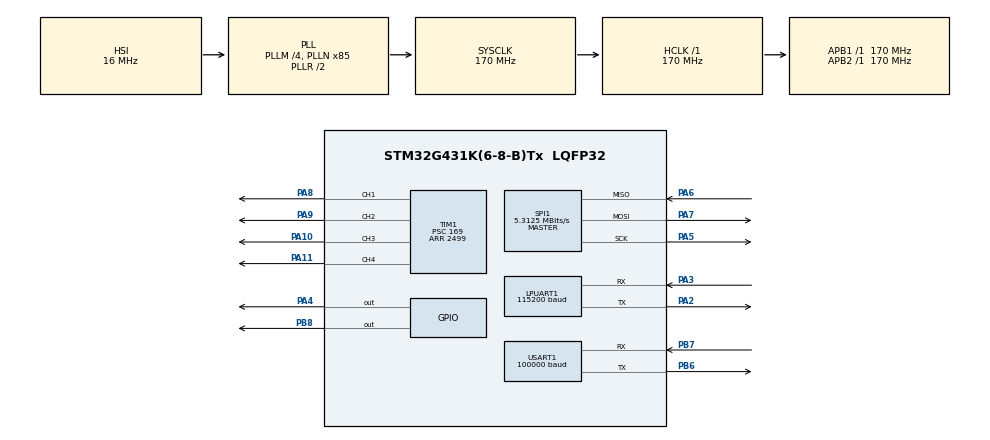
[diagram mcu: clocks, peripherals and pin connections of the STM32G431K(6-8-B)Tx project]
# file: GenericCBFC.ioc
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Dma.Request0=USART1_RX
Dma.USART1_RX.0.Direction=DMA_PERIPH_TO_MEMORY
Dma.USART1_RX.0.EventEnable=DISABLE
Dma.USART1_RX.0.Instance=DMA1_Channel1
Dma.USART1_RX.0.MemDataAlignment=DMA_MDATAALIGN_BYTE
Dma.USART1_RX.0.MemInc=DMA_MINC_ENABLE
Dma.USART1_RX.0.Mode=DMA_NORMAL
Dma.USART1_RX.0.PeriphDataAlignment=DMA_PDATAALIGN_BYTE
Dma.USART1_RX.0.PeriphInc=DMA_PINC_DISABLE
Dma.USART1_RX.0.Polarity=HAL_DMAMUX_REQ_GEN_RISING
Dma.USART1_RX.0.Priority=DMA_PRIORITY_VERY_HIGH
Dma.USART1_RX.0.RequestNumber=1
Dma.USART1_RX.0.SignalID=NONE
Dma.USART1_RX.0.SyncEnable=DISABLE
Dma.USART1_RX.0.SyncPolarity=HAL_DMAMUX_SYNC_NO_EVENT
Dma.USART1_RX.0.SyncRequestNumber=1
Dma.USART1_RX.0.SyncSignalID=NONE
LPUART1.BaudRate=115200
Mcu.Family=STM32G4
Mcu.Name=STM32G431K(6-8-B)Tx
Mcu.Package=LQFP32
NVIC.DMA1_Channel1_IRQn=true\:0\:0\:false\:false\:true\:false\:true\:true
NVIC.PriorityGroup=NVIC_PRIORITYGROUP_4
NVIC.TIM6_DAC_IRQn=true\:0\:0\:false\:false\:true\:true\:true\:true
PA10.Signal=S_TIM1_CH3
PA11.Signal=S_TIM1_CH4
PA2.Mode=Asynchronous
PA2.Signal=LPUART1_TX
PA3.Mode=Asynchronous
PA3.Signal=LPUART1_RX
PA4.Signal=GPIO_Output
PA5.Mode=Full_Duplex_Master
PA5.Signal=SPI1_SCK
PA6.Mode=Full_Duplex_Master
PA6.Signal=SPI1_MISO
PA7.Mode=Full_Duplex_Master
PA7.Signal=SPI1_MOSI
PA8.Signal=S_TIM1_CH1
PA9.Signal=S_TIM1_CH2
PB6.Mode=Asynchronous
PB6.Signal=USART1_TX
PB7.Mode=Asynchronous
PB7.Signal=USART1_RX
PB8-BOOT0.Signal=GPIO_Output
ProjectManager.HeapSize=0x200
ProjectManager.StackSize=0x400
ProjectManager.TargetToolchain=STM32CubeIDE
RCC.ADC12Freq_Value=170000000
RCC.AHBFreq_Value=170000000
RCC.APB1Freq_Value=170000000
RCC.APB1TimFreq_Value=170000000
RCC.APB2Freq_Value=170000000
RCC.APB2TimFreq_Value=170000000
RCC.CortexFreq_Value=170000000
RCC.EXTERNAL_CLOCK_VALUE=12288000
RCC.HCLKFreq_Value=170000000
RCC.HSE_VALUE=8000000
RCC.HSI48_VALUE=48000000
RCC.HSI_VALUE=16000000
RCC.LSE_VALUE=32768
RCC.PLLM=RCC_PLLM_DIV4
RCC.PLLN=85
RCC.SYSCLKFreq_VALUE=170000000
RCC.SYSCLKSource=RCC_SYSCLKSOURCE_PLLCLK
RCC.USBFreq_Value=170000000
RCC.VCOOutputFreq_Value=340000000
SH.S_TIM1_CH1.0=TIM1_CH1,PWM Generation1 CH1
SH.S_TIM1_CH2.0=TIM1_CH2,PWM Generation2 CH2
SH.S_TIM1_CH3.0=TIM1_CH3,PWM Generation3 CH3
SH.S_TIM1_CH4.0=TIM1_CH4,PWM Generation4 CH4
SPI1.BaudRatePrescaler=SPI_BAUDRATEPRESCALER_32
SPI1.CalculateBaudRate=5.3125 MBits/s
SPI1.DataSize=SPI_DATASIZE_8BIT
SPI1.Direction=SPI_DIRECTION_2LINES
SPI1.Mode=SPI_MODE_MASTER
SPI1.VirtualType=VM_MASTER
TIM1.Channel-PWM\ Generation1\ CH1=TIM_CHANNEL_1
TIM1.Channel-PWM\ Generation2\ CH2=TIM_CHANNEL_2
TIM1.Channel-PWM\ Generation3\ CH3=TIM_CHANNEL_3
TIM1.Channel-PWM\ Generation4\ CH4=TIM_CHANNEL_4
TIM1.PeriodNoDither=2499
TIM1.Prescaler=169
TIM6.PeriodNoDither=2499
TIM6.Prescaler=169
USART1.BaudRate=100000
USART1.Parity=PARITY_EVEN
USART1.RxPinLevelInvertParam=ADVFEATURE_RXINV_ENABLE
USART1.StopBits=STOPBITS_2
USART1.VirtualMode-Asynchronous=VM_ASYNC
USART1.WordLength=WORDLENGTH_9B
VP_SYS_VS_DBSignals.Mode=DisableDeadBatterySignals
VP_TIM6_VS_ClockSourceINT.Mode=Enable_Timer
board=NUCLEO-G431KB

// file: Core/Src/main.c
/* USER CODE BEGIN Header */
/**
  ******************************************************************************
  * @file           : main.c
  * @brief          : Main program body
  ******************************************************************************
  * @attention
  *
  * Copyright (c) 2025 STMicroelectronics.
  * All rights reserved.
  *
  * This software is licensed under terms that can be found in the LICENSE file
  * in the root directory of this software component.
  * If no LICENSE file comes with this software, it is provided AS-IS.
  *
  ******************************************************************************
  */
/* USER CODE END Header */
#include "main.h"
#include "dma.h"
#include "usart.h"
#include "spi.h"
#include "tim.h"
#include "gpio.h"

/* USER CODE BEGIN Includes */
#include "wrapper.hpp"
#include <stdio.h>
/* USER CODE END Includes */

void SystemClock_Config(void);

/* USER CODE BEGIN 0 */
int __io_putchar(int ch){

	HAL_UART_Transmit(&hlpuart1, (uint8_t *)&ch,1,100);
	return ch;
}
/* USER CODE END 0 */

int main(void)
{

  /* MCU Configuration--------------------------------------------------------*/

  /* Reset of all peripherals, Initializes the Flash interface and the Systick. */
  HAL_Init();

  /* Configure the system clock */
  SystemClock_Config();

  /* Initialize all configured peripherals */
  MX_GPIO_Init();
  MX_DMA_Init();
  MX_LPUART1_UART_Init();
  MX_USART1_UART_Init();
  MX_SPI1_Init();
  MX_TIM1_Init();
  MX_TIM6_Init();
  /* USER CODE BEGIN 2 */
  init();
  /* USER CODE END 2 */

  /* Infinite loop */
  while (1)
  {

    /* USER CODE BEGIN 3 */
	  loop();
  }
  /* USER CODE END 3 */
}

void SystemClock_Config(void)
{
  RCC_OscInitTypeDef RCC_OscInitStruct = {0};
  RCC_ClkInitTypeDef RCC_ClkInitStruct = {0};

  /** Configure the main internal regulator output voltage
  */
  HAL_PWREx_ControlVoltageScaling(PWR_REGULATOR_VOLTAGE_SCALE1_BOOST);

  /** Initializes the RCC Oscillators according to the specified parameters
  * in the RCC_OscInitTypeDef structure.
  */
  RCC_OscInitStruct.OscillatorType = RCC_OSCILLATORTYPE_HSI;
  RCC_OscInitStruct.HSIState = RCC_HSI_ON;
  RCC_OscInitStruct.HSICalibrationValue = RCC_HSICALIBRATION_DEFAULT;
  RCC_OscInitStruct.PLL.PLLState = RCC_PLL_ON;
  RCC_OscInitStruct.PLL.PLLSource = RCC_PLLSOURCE_HSI;
  RCC_OscInitStruct.PLL.PLLM = RCC_PLLM_DIV4;
  RCC_OscInitStruct.PLL.PLLN = 85;
  RCC_OscInitStruct.PLL.PLLP = RCC_PLLP_DIV2;
  RCC_OscInitStruct.PLL.PLLQ = RCC_PLLQ_DIV2;
  RCC_OscInitStruct.PLL.PLLR = RCC_PLLR_DIV2;
  if (HAL_RCC_OscConfig(&RCC_OscInitStruct) != HAL_OK)
  {
    Error_Handler();
  }

  /** Initializes the CPU, AHB and APB buses clocks
  */
  RCC_ClkInitStruct.ClockType = RCC_CLOCKTYPE_HCLK|RCC_CLOCKTYPE_SYSCLK
                              |RCC_CLOCKTYPE_PCLK1|RCC_CLOCKTYPE_PCLK2;
  RCC_ClkInitStruct.SYSCLKSource = RCC_SYSCLKSOURCE_PLLCLK;
  RCC_ClkInitStruct.AHBCLKDivider = RCC_SYSCLK_DIV1;
  RCC_ClkInitStruct.APB1CLKDivider = RCC_HCLK_DIV1;
  RCC_ClkInitStruct.APB2CLKDivider = RCC_HCLK_DIV1;

  if (HAL_RCC_ClockConfig(&RCC_ClkInitStruct, FLASH_LATENCY_4) != HAL_OK)
  {
    Error_Handler();
  }
}

void Error_Handler(void)
{
  __disable_irq();
  while (1)
  {
  }
}
